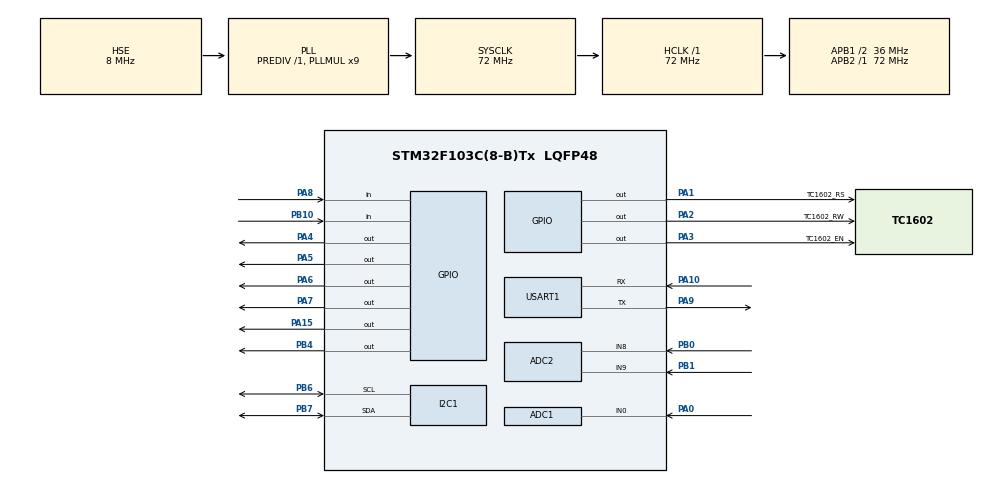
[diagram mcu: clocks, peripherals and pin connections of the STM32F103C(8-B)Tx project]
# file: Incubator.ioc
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ADC1.Channel-5\#ChannelRegularConversion=ADC_CHANNEL_0
ADC1.ContinuousConvMode=ENABLE
ADC1.NbrOfConversionFlag=1
ADC1.Rank-5\#ChannelRegularConversion=1
ADC1.SamplingTime-5\#ChannelRegularConversion=ADC_SAMPLETIME_55CYCLES_5
ADC1.master=1
ADC2.Channel-0\#ChannelRegularConversion=ADC_CHANNEL_8
ADC2.ContinuousConvMode=DISABLE
ADC2.NbrOfConversionFlag=1
ADC2.Rank-0\#ChannelRegularConversion=1
ADC2.SamplingTime-0\#ChannelRegularConversion=ADC_SAMPLETIME_55CYCLES_5
I2C1.I2C_Mode=I2C_Fast
Mcu.Family=STM32F1
Mcu.Name=STM32F103C(8-B)Tx
Mcu.Package=LQFP48
NVIC.PriorityGroup=NVIC_PRIORITYGROUP_4
NVIC.RCC_IRQn=true\:0\:0\:false\:false\:true\:true\:false\:true
PA0-WKUP.Signal=ADCx_IN0
PA1.GPIO_Label=TC1602_RS
PA1.GPIO_Speed=GPIO_SPEED_FREQ_HIGH
PA1.Signal=GPIO_Output
PA10.Mode=Asynchronous
PA10.Signal=USART1_RX
PA15.Signal=GPIO_Output
PA2.GPIO_Label=TC1602_RW
PA2.GPIO_Speed=GPIO_SPEED_FREQ_HIGH
PA2.Signal=GPIO_Output
PA3.GPIO_Label=TC1602_EN
PA3.GPIO_Speed=GPIO_SPEED_FREQ_HIGH
PA3.Signal=GPIO_Output
PA4.GPIO_Speed=GPIO_SPEED_FREQ_HIGH
PA4.Signal=GPIO_Output
PA5.GPIO_Speed=GPIO_SPEED_FREQ_HIGH
PA5.Signal=GPIO_Output
PA6.GPIO_Speed=GPIO_SPEED_FREQ_HIGH
PA6.Signal=GPIO_Output
PA7.GPIO_Speed=GPIO_SPEED_FREQ_HIGH
PA7.Signal=GPIO_Output
PA8.Signal=GPIO_Input
PA9.Mode=Asynchronous
PA9.Signal=USART1_TX
PB0.Signal=ADCx_IN8
PB1.Signal=ADCx_IN9
PB10.Signal=GPIO_Input
PB4.Signal=GPIO_Output
PB6.Mode=I2C
PB6.Signal=I2C1_SCL
PB7.Mode=I2C
PB7.Signal=I2C1_SDA
PD0-OSC_IN.Mode=HSE-External-Oscillator
PD0-OSC_IN.Signal=RCC_OSC_IN
PD1-OSC_OUT.Mode=HSE-External-Oscillator
PD1-OSC_OUT.Signal=RCC_OSC_OUT
ProjectManager.HeapSize=0x200
ProjectManager.StackSize=0x400
ProjectManager.TargetToolchain=STM32CubeIDE
RCC.ADCPresc=RCC_ADCPCLK2_DIV8
RCC.AHBFreq_Value=72000000
RCC.APB1CLKDivider=RCC_HCLK_DIV2
RCC.APB1Freq_Value=36000000
RCC.APB1TimFreq_Value=72000000
RCC.APB2Freq_Value=72000000
RCC.APB2TimFreq_Value=72000000
RCC.HCLKFreq_Value=72000000
RCC.PLLMUL=RCC_PLL_MUL9
RCC.PLLSourceVirtual=RCC_PLLSOURCE_HSE
RCC.SYSCLKFreq_VALUE=72000000
RCC.SYSCLKSource=RCC_SYSCLKSOURCE_PLLCLK
RCC.USBFreq_Value=72000000
SH.ADCx_IN0.0=ADC1_IN0,IN0
SH.ADCx_IN8.0=ADC2_IN8,IN8
SH.ADCx_IN9.0=ADC2_IN9,IN9
TIM4.Prescaler=72-1
USART1.VirtualMode=VM_ASYNC
VP_SYS_VS_ND.Mode=No_Debug
VP_TIM4_VS_ClockSourceINT.Mode=Internal
board=custom

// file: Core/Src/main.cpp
/* USER CODE BEGIN Header */
/**
  ******************************************************************************
  * @file           : main.c
  * @brief          : Main program body
  ******************************************************************************
  * @attention
  *
  * Copyright (c) 2024 STMicroelectronics.
  * All rights reserved.
  *
  * This software is licensed under terms that can be found in the LICENSE file
  * in the root directory of this software component.
  * If no LICENSE file comes with this software, it is provided AS-IS.
  *
  ******************************************************************************
  */
/* USER CODE END Header */
#include "main.h"

/* USER CODE BEGIN Includes */
#include "Incubator/Incubator.h"
/* USER CODE END Includes */

/* USER CODE BEGIN PD */
#ifndef INCUBATOR_SOFTWARE_VERSION
#define INCUBATOR_SOFTWARE_VERSION "Hata"
#endif // INCUBATOR_SOFTWARE_VERSION
/* USER CODE END PD */

/* USER CODE BEGIN PM */
  const char *INCUBATOR_VERSION = INCUBATOR_SOFTWARE_VERSION;
/* USER CODE END PM */

ADC_HandleTypeDef hadc1;
ADC_HandleTypeDef hadc2;

I2C_HandleTypeDef hi2c1;

TIM_HandleTypeDef htim4;

UART_HandleTypeDef huart1;

/* USER CODE BEGIN PV */
Incubator incubator(INCUBATOR_VERSION);
/* USER CODE END PV */

void SystemClock_Config(void);
static void MX_GPIO_Init(void);
static void MX_TIM4_Init(void);
static void MX_USART1_UART_Init(void);
static void MX_I2C1_Init(void);
static void MX_ADC1_Init(void);
static void MX_ADC2_Init(void);

int main(void)
{

  /* MCU Configuration--------------------------------------------------------*/

  /* Reset of all peripherals, Initializes the Flash interface and the Systick. */
  HAL_Init();

  /* Configure the system clock */
  SystemClock_Config();

  /* Initialize all configured peripherals */
  MX_GPIO_Init();
  MX_TIM4_Init();
  MX_USART1_UART_Init();
  MX_I2C1_Init();
  MX_ADC1_Init();
  MX_ADC2_Init();

  /* Infinite loop */
  /* USER CODE BEGIN WHILE */
  incubator.Initialize();
  while (1)
  {
    /* USER CODE END WHILE */

    /* USER CODE BEGIN 3 */
	  incubator.Run();
  }
  /* USER CODE END 3 */
}

void SystemClock_Config(void)
{
  RCC_OscInitTypeDef RCC_OscInitStruct = {0};
  RCC_ClkInitTypeDef RCC_ClkInitStruct = {0};
  RCC_PeriphCLKInitTypeDef PeriphClkInit = {0};

  /** Initializes the RCC Oscillators according to the specified parameters
  * in the RCC_OscInitTypeDef structure.
  */
  RCC_OscInitStruct.OscillatorType = RCC_OSCILLATORTYPE_HSE;
  RCC_OscInitStruct.HSEState = RCC_HSE_ON;
  RCC_OscInitStruct.HSEPredivValue = RCC_HSE_PREDIV_DIV1;
  RCC_OscInitStruct.HSIState = RCC_HSI_ON;
  RCC_OscInitStruct.PLL.PLLState = RCC_PLL_ON;
  RCC_OscInitStruct.PLL.PLLSource = RCC_PLLSOURCE_HSE;
  RCC_OscInitStruct.PLL.PLLMUL = RCC_PLL_MUL9;
  if (HAL_RCC_OscConfig(&RCC_OscInitStruct) != HAL_OK)
  {
    Error_Handler();
  }

  /** Initializes the CPU, AHB and APB buses clocks
  */
  RCC_ClkInitStruct.ClockType = RCC_CLOCKTYPE_HCLK|RCC_CLOCKTYPE_SYSCLK
                              |RCC_CLOCKTYPE_PCLK1|RCC_CLOCKTYPE_PCLK2;
  RCC_ClkInitStruct.SYSCLKSource = RCC_SYSCLKSOURCE_PLLCLK;
  RCC_ClkInitStruct.AHBCLKDivider = RCC_SYSCLK_DIV1;
  RCC_ClkInitStruct.APB1CLKDivider = RCC_HCLK_DIV2;
  RCC_ClkInitStruct.APB2CLKDivider = RCC_HCLK_DIV1;

  if (HAL_RCC_ClockConfig(&RCC_ClkInitStruct, FLASH_LATENCY_2) != HAL_OK)
  {
    Error_Handler();
  }
  PeriphClkInit.PeriphClockSelection = RCC_PERIPHCLK_ADC;
  PeriphClkInit.AdcClockSelection = RCC_ADCPCLK2_DIV8;
  if (HAL_RCCEx_PeriphCLKConfig(&PeriphClkInit) != HAL_OK)
  {
    Error_Handler();
  }
}

static void MX_ADC1_Init(void)
{

  ADC_ChannelConfTypeDef sConfig = {0};

  /** Common config
  */
  hadc1.Instance = ADC1;
  hadc1.Init.ScanConvMode = ADC_SCAN_DISABLE;
  hadc1.Init.ContinuousConvMode = ENABLE;
  hadc1.Init.DiscontinuousConvMode = DISABLE;
  hadc1.Init.ExternalTrigConv = ADC_SOFTWARE_START;
  hadc1.Init.DataAlign = ADC_DATAALIGN_RIGHT;
  hadc1.Init.NbrOfConversion = 1;
  if (HAL_ADC_Init(&hadc1) != HAL_OK)
  {
    Error_Handler();
  }

  /** Configure Regular Channel
  */
  sConfig.Channel = ADC_CHANNEL_0;
  sConfig.Rank = ADC_REGULAR_RANK_1;
  sConfig.SamplingTime = ADC_SAMPLETIME_55CYCLES_5;
  if (HAL_ADC_ConfigChannel(&hadc1, &sConfig) != HAL_OK)
  {
    Error_Handler();
  }

}

static void MX_ADC2_Init(void)
{

  ADC_ChannelConfTypeDef sConfig = {0};

  /** Common config
  */
  hadc2.Instance = ADC2;
  hadc2.Init.ScanConvMode = ADC_SCAN_DISABLE;
  hadc2.Init.ContinuousConvMode = DISABLE;
  hadc2.Init.DiscontinuousConvMode = DISABLE;
  hadc2.Init.ExternalTrigConv = ADC_SOFTWARE_START;
  hadc2.Init.DataAlign = ADC_DATAALIGN_RIGHT;
  hadc2.Init.NbrOfConversion = 1;
  if (HAL_ADC_Init(&hadc2) != HAL_OK)
  {
    Error_Handler();
  }

  /** Configure Regular Channel
  */
  sConfig.Channel = ADC_CHANNEL_8;
  sConfig.Rank = ADC_REGULAR_RANK_1;
  sConfig.SamplingTime = ADC_SAMPLETIME_55CYCLES_5;
  if (HAL_ADC_ConfigChannel(&hadc2, &sConfig) != HAL_OK)
  {
    Error_Handler();
  }

}

static void MX_I2C1_Init(void)
{

  hi2c1.Instance = I2C1;
  hi2c1.Init.ClockSpeed = 400000;
  hi2c1.Init.DutyCycle = I2C_DUTYCYCLE_2;
  hi2c1.Init.OwnAddress1 = 0;
  hi2c1.Init.AddressingMode = I2C_ADDRESSINGMODE_7BIT;
  hi2c1.Init.DualAddressMode = I2C_DUALADDRESS_DISABLE;
  hi2c1.Init.OwnAddress2 = 0;
  hi2c1.Init.GeneralCallMode = I2C_GENERALCALL_DISABLE;
  hi2c1.Init.NoStretchMode = I2C_NOSTRETCH_DISABLE;
  if (HAL_I2C_Init(&hi2c1) != HAL_OK)
  {
    Error_Handler();
  }

}

static void MX_TIM4_Init(void)
{

  TIM_ClockConfigTypeDef sClockSourceConfig = {0};
  TIM_MasterConfigTypeDef sMasterConfig = {0};

  htim4.Instance = TIM4;
  htim4.Init.Prescaler = 72-1;
  htim4.Init.CounterMode = TIM_COUNTERMODE_UP;
  htim4.Init.Period = 65535;
  htim4.Init.ClockDivision = TIM_CLOCKDIVISION_DIV1;
  htim4.Init.AutoReloadPreload = TIM_AUTORELOAD_PRELOAD_DISABLE;
  if (HAL_TIM_Base_Init(&htim4) != HAL_OK)
  {
    Error_Handler();
  }
  sClockSourceConfig.ClockSource = TIM_CLOCKSOURCE_INTERNAL;
  if (HAL_TIM_ConfigClockSource(&htim4, &sClockSourceConfig) != HAL_OK)
  {
    Error_Handler();
  }
  sMasterConfig.MasterOutputTrigger = TIM_TRGO_RESET;
  sMasterConfig.MasterSlaveMode = TIM_MASTERSLAVEMODE_DISABLE;
  if (HAL_TIMEx_MasterConfigSynchronization(&htim4, &sMasterConfig) != HAL_OK)
  {
    Error_Handler();
  }

}

static void MX_USART1_UART_Init(void)
{

  huart1.Instance = USART1;
  huart1.Init.BaudRate = 115200;
  huart1.Init.WordLength = UART_WORDLENGTH_8B;
  huart1.Init.StopBits = UART_STOPBITS_1;
  huart1.Init.Parity = UART_PARITY_NONE;
  huart1.Init.Mode = UART_MODE_TX_RX;
  huart1.Init.HwFlowCtl = UART_HWCONTROL_NONE;
  huart1.Init.OverSampling = UART_OVERSAMPLING_16;
  if (HAL_UART_Init(&huart1) != HAL_OK)
  {
    Error_Handler();
  }

}

static void MX_GPIO_Init(void)
{
  GPIO_InitTypeDef GPIO_InitStruct = {0};

  /* GPIO Ports Clock Enable */
  __HAL_RCC_GPIOD_CLK_ENABLE();
  __HAL_RCC_GPIOA_CLK_ENABLE();
  __HAL_RCC_GPIOB_CLK_ENABLE();

  /*Configure GPIO pin Output Level */
  HAL_GPIO_WritePin(GPIOA, TC1602_RS_Pin|TC1602_RW_Pin|TC1602_EN_Pin|GPIO_PIN_4
                          |GPIO_PIN_5|GPIO_PIN_6|GPIO_PIN_7|GPIO_PIN_15, GPIO_PIN_RESET);

  /*Configure GPIO pin Output Level */
  HAL_GPIO_WritePin(GPIOB, GPIO_PIN_4, GPIO_PIN_RESET);

  /*Configure GPIO pins : TC1602_RS_Pin TC1602_RW_Pin TC1602_EN_Pin PA4
                           PA5 PA6 PA7 */
  GPIO_InitStruct.Pin = TC1602_RS_Pin|TC1602_RW_Pin|TC1602_EN_Pin|GPIO_PIN_4
                          |GPIO_PIN_5|GPIO_PIN_6|GPIO_PIN_7;
  GPIO_InitStruct.Mode = GPIO_MODE_OUTPUT_PP;
  GPIO_InitStruct.Pull = GPIO_NOPULL;
  GPIO_InitStruct.Speed = GPIO_SPEED_FREQ_HIGH;
  HAL_GPIO_Init(GPIOA, &GPIO_InitStruct);

  /*Configure GPIO pin : PB10 */
  GPIO_InitStruct.Pin = GPIO_PIN_10;
  GPIO_InitStruct.Mode = GPIO_MODE_INPUT;
  GPIO_InitStruct.Pull = GPIO_NOPULL;
  HAL_GPIO_Init(GPIOB, &GPIO_InitStruct);

  /*Configure GPIO pin : PA8 */
  GPIO_InitStruct.Pin = GPIO_PIN_8;
  GPIO_InitStruct.Mode = GPIO_MODE_INPUT;
  GPIO_InitStruct.Pull = GPIO_NOPULL;
  HAL_GPIO_Init(GPIOA, &GPIO_InitStruct);

  /*Configure GPIO pin : PA15 */
  GPIO_InitStruct.Pin = GPIO_PIN_15;
  GPIO_InitStruct.Mode = GPIO_MODE_OUTPUT_PP;
  GPIO_InitStruct.Pull = GPIO_NOPULL;
  GPIO_InitStruct.Speed = GPIO_SPEED_FREQ_LOW;
  HAL_GPIO_Init(GPIOA, &GPIO_InitStruct);

  /*Configure GPIO pin : PB4 */
  GPIO_InitStruct.Pin = GPIO_PIN_4;
  GPIO_InitStruct.Mode = GPIO_MODE_OUTPUT_PP;
  GPIO_InitStruct.Pull = GPIO_NOPULL;
  GPIO_InitStruct.Speed = GPIO_SPEED_FREQ_LOW;
  HAL_GPIO_Init(GPIOB, &GPIO_InitStruct);

}

void Error_Handler(void)
{
  __disable_irq();
  while (1)
  {
  }
}
